# HC32M413 register map
File version: 1.0
CPU: CM4 r0p1, little endian, MPU, FPU, 4 interrupt priority bits
Registers are 32-bit, read-write, reset 0x0 unless marked. A register's access mark holds for its fields unless they carry their own. Offsets are from the block's base; [hi:lo] are bit positions; {n}, {i} and the like mark numbered series.

## CMP_COMMON
Base 0x4004A000; alternate view of CMP1
0x0C DADR 16-bit
  [11:0] DADR
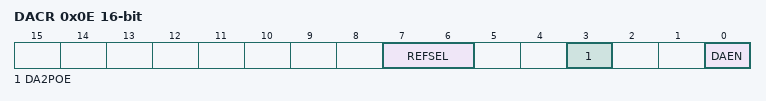
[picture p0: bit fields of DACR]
0x0E DACR 16-bit
  [7:6] REFSEL, [3] DA2POE, [0] DAEN

## CMU
Base 0x40054400
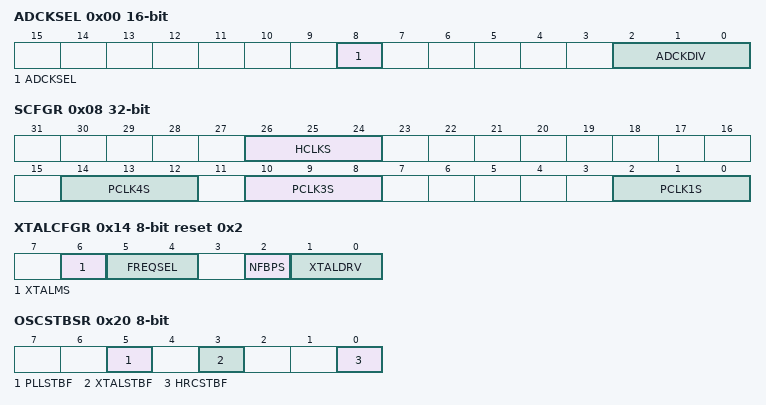
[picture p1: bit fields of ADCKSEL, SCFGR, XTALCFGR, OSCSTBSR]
0x00 ADCKSEL 16-bit
  [8] ADCKSEL, [2:0] ADCKDIV
0x04 XTALSTDSR 8-bit
  [0] XTALSTDF
0x08 SCFGR
  [26:24] HCLKS, [14:12] PCLK4S, [10:8] PCLK3S, [2:0] PCLK1S
0x0C CKSWR 8-bit reset 0x1
  [2:0] CKSW
0x10 XTALCR 8-bit reset 0x1
  [0] XTALSTP
0x14 XTALCFGR 8-bit reset 0x2
  [6] XTALMS, [5:4] FREQSEL, [2] NFBPS, [1:0] XTALDRV
0x15 XTALSTBCR 8-bit
  [2:0] XTALSTB
0x18 HRCCR 8-bit
  [0] HRCSTP
0x20 OSCSTBSR 8-bit ro
  [5] PLLSTBF, [3] XTALSTBF, [0] HRCSTBF
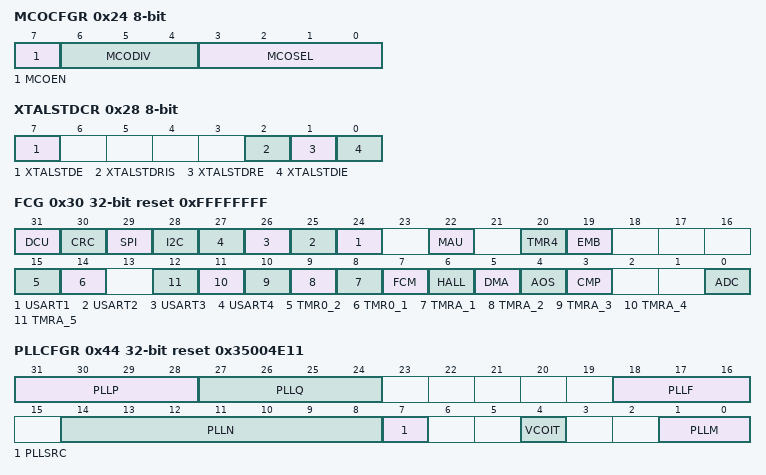
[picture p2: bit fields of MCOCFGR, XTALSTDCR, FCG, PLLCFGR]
0x24 MCOCFGR 8-bit
  [7] MCOEN, [6:4] MCODIV, [3:0] MCOSEL
0x28 XTALSTDCR 8-bit
  [7] XTALSTDE, [2] XTALSTDRIS, [1] XTALSTDRE, [0] XTALSTDIE
0x30 FCG reset 0xFFFFFFFF
  [31] DCU, [30] CRC, [29] SPI, [28] I2C, [n+23] USART{n} (n=1..4), [22] MAU, [20] TMR4, [19] EMB, [15] TMR0_2, [14] TMR0_1, [n+7] TMRA_{n} (n=1..5), [7] FCM, [6] HALL, [5] DMA, [4] AOS, [3] CMP, [0] ADC
0x3C LRCCR 8-bit
  [0] LRCSTP
0x40 MRCCR 8-bit
  [0] MRCSTP
0x44 PLLCFGR reset 0x35004E11
  [31:28] PLLP, [27:24] PLLQ, [18:16] PLLF, [14:8] PLLN, [7] PLLSRC, [4] VCOIT, [1:0] PLLM
0x48 PLLCR 8-bit reset 0x1
  [0] PLLOFF

## CRC
Base 0x40050400
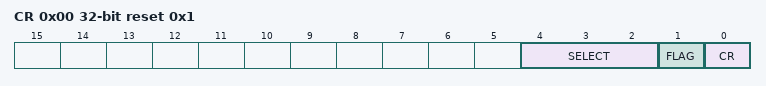
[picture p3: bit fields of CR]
0x00 CR reset 0x1
  [4:2] SELECT, [1] FLAG ro, [0] CR
0x04 RESLT1
0x08 RESLT2
{0x80+4i} DAT{i} wo (i=0..31)

## DBGC
Base 0xE0042000
0x0C CHIPID ro reset 0x58480413
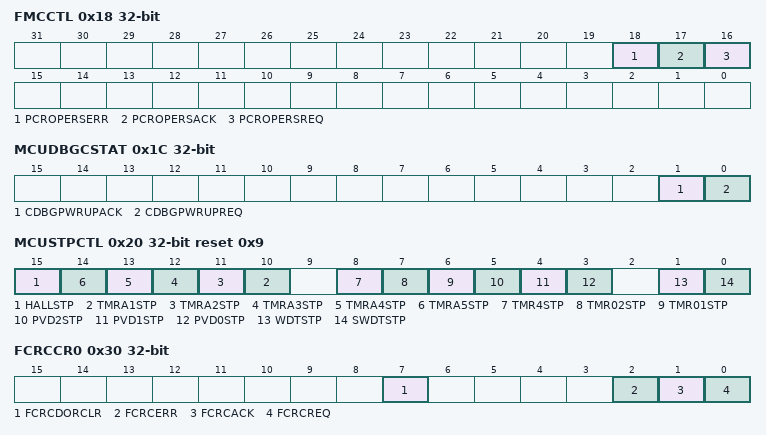
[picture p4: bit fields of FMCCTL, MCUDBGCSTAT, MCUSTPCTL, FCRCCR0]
0x18 FMCCTL
  [18] PCROPERSERR, [17] PCROPERSACK, [16] PCROPERSREQ
0x1C MCUDBGCSTAT
  [1] CDBGPWRUPACK, [0] CDBGPWRUPREQ
0x20 MCUSTPCTL reset 0x9
  [15] HALLSTP, [n+9] TMRA{n}STP (n=1..5), [8] TMR4STP, [7] TMR02STP, [6] TMR01STP, [5] PVD2STP, [4] PVD1STP, [3] PVD0STP, [1] WDTSTP, [0] SWDTSTP
0x30 FCRCCR0
  [7] FCRCDORCLR, [2] FCRCERR, [1] FCRCACK, [0] FCRCREQ
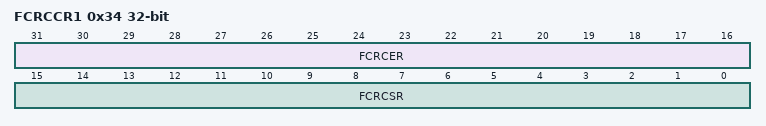
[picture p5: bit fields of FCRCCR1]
0x34 FCRCCR1
  [31:16] FCRCER, [15:0] FCRCSR
0x38 FCRCDOR ro
0x3C FCRCREF ro

## DCU
Base 0x40052000
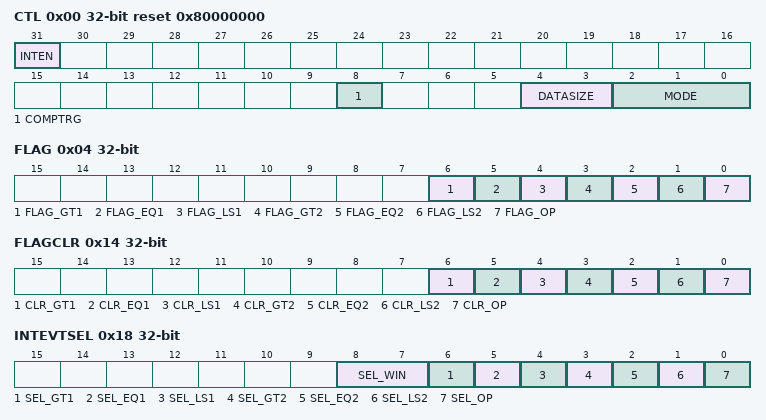
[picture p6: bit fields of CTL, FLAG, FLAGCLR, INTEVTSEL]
0x00 CTL reset 0x80000000
  [31] INTEN, [8] COMPTRG, [4:3] DATASIZE, [2:0] MODE
0x04 FLAG ro
  [6] FLAG_GT1, [5] FLAG_EQ1, [4] FLAG_LS1, [3] FLAG_GT2, [2] FLAG_EQ2, [1] FLAG_LS2, [0] FLAG_OP
{0x8+4i} DATA{i} (i=0..2)
0x14 FLAGCLR wo
  [6] CLR_GT1, [5] CLR_EQ1, [4] CLR_LS1, [3] CLR_GT2, [2] CLR_EQ2, [1] CLR_LS2, [0] CLR_OP
0x18 INTEVTSEL
  [8:7] SEL_WIN, [6] SEL_GT1, [5] SEL_EQ1, [4] SEL_LS1, [3] SEL_GT2, [2] SEL_EQ2, [1] SEL_LS2, [0] SEL_OP

## DMA
Base 0x40053000
0x00 EN
  [0] EN
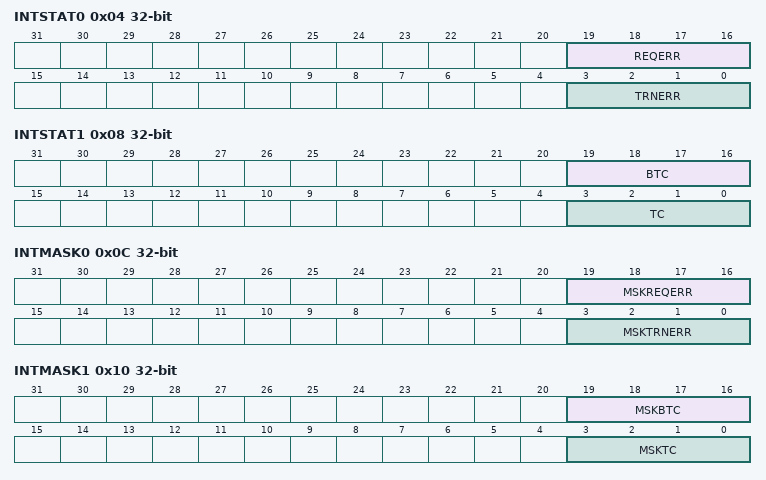
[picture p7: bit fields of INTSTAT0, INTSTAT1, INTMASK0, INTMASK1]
0x04 INTSTAT0 ro
  [19:16] REQERR, [3:0] TRNERR
0x08 INTSTAT1 ro
  [19:16] BTC, [3:0] TC
0x0C INTMASK0
  [19:16] MSKREQERR, [3:0] MSKTRNERR
0x10 INTMASK1
  [19:16] MSKBTC, [3:0] MSKTC
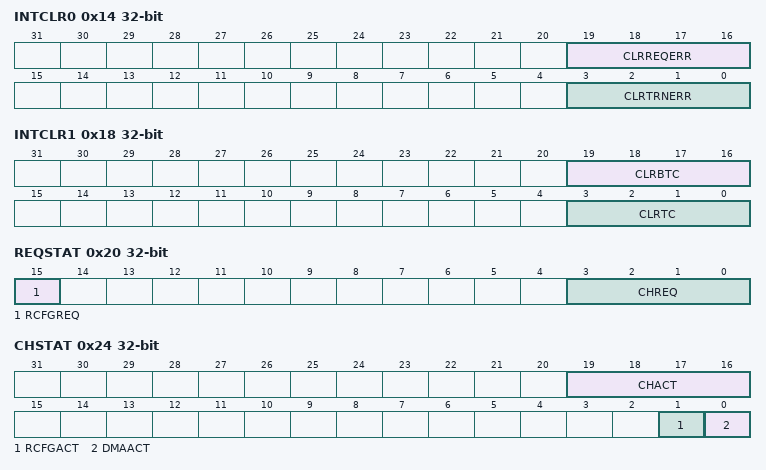
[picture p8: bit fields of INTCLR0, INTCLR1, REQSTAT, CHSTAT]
0x14 INTCLR0
  [19:16] CLRREQERR, [3:0] CLRTRNERR
0x18 INTCLR1
  [19:16] CLRBTC, [3:0] CLRTC
0x1C CHEN
  [3:0] CHEN
0x20 REQSTAT ro
  [15] RCFGREQ, [3:0] CHREQ
0x24 CHSTAT ro
  [19:16] CHACT, [1] RCFGACT, [0] DMAACT
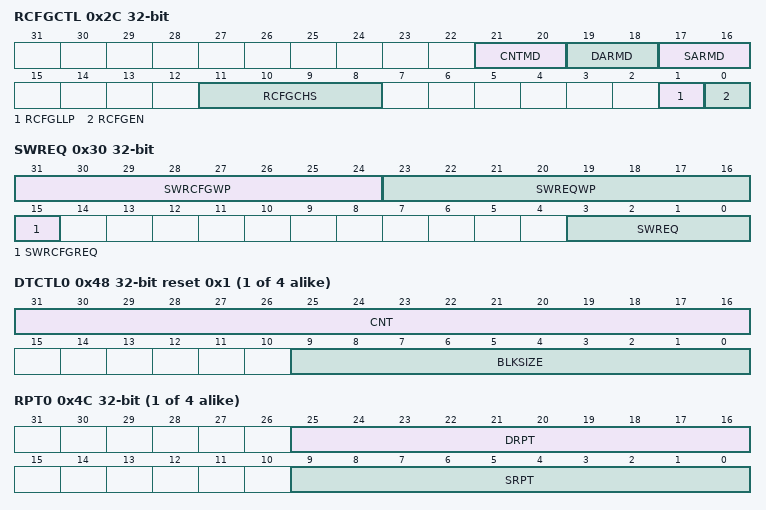
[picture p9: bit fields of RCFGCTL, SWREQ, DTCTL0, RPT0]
0x2C RCFGCTL
  [21:20] CNTMD, [19:18] DARMD, [17:16] SARMD, [11:8] RCFGCHS, [1] RCFGLLP, [0] RCFGEN
0x30 SWREQ wo
  [31:24] SWRCFGWP, [23:16] SWREQWP, [15] SWRCFGREQ, [3:0] SWREQ
0x34 CHENCLR wo
  [3:0] CHENCLR
{0x40+0x40*i} SAR{i} (i=0..3)
{0x44+0x40*i} DAR{i} (i=0..3)
{0x48+0x40*i} DTCTL{i} reset 0x1 (i=0..3)
  [31:16] CNT, [9:0] BLKSIZE
{0x4C+0x40*i} RPT{i} (i=0..3)
  [25:16] DRPT, [9:0] SRPT
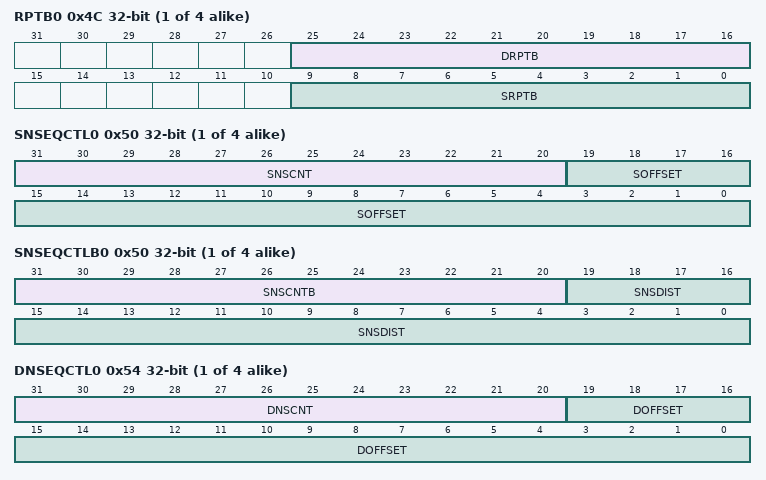
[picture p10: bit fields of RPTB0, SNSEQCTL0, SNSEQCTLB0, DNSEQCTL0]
{0x4C+0x40*i} RPTB{i} (alternate view of RPT{i}) (i=0..3)
  [25:16] DRPTB, [9:0] SRPTB
{0x50+0x40*i} SNSEQCTL{i} (i=0..3)
  [31:20] SNSCNT, [19:0] SOFFSET
{0x50+0x40*i} SNSEQCTLB{i} (alternate view of SNSEQCTL{i}) (i=0..3)
  [31:20] SNSCNTB, [19:0] SNSDIST
{0x54+0x40*i} DNSEQCTL{i} (i=0..3)
  [31:20] DNSCNT, [19:0] DOFFSET
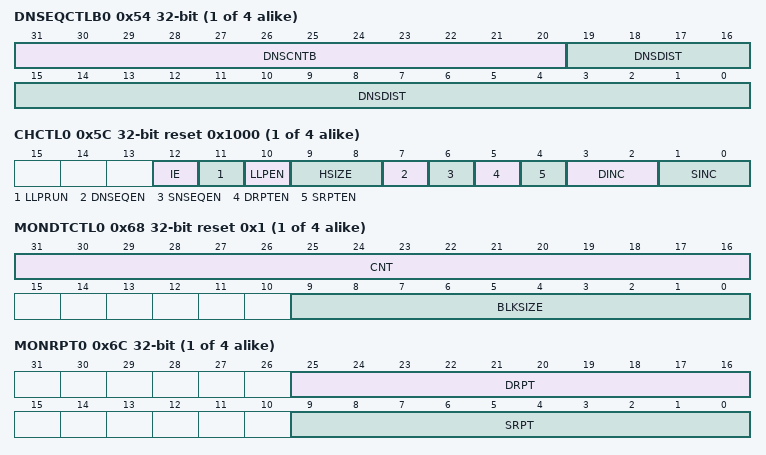
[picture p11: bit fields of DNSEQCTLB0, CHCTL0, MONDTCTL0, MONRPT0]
{0x54+0x40*i} DNSEQCTLB{i} (alternate view of DNSEQCTL{i}) (i=0..3)
  [31:20] DNSCNTB, [19:0] DNSDIST
{0x58+0x40*i} LLP{i} (i=0..3)
  [31:2] LLP
{0x5C+0x40*i} CHCTL{i} reset 0x1000 (i=0..3)
  [12] IE, [11] LLPRUN, [10] LLPEN, [9:8] HSIZE, [7] DNSEQEN, [6] SNSEQEN, [5] DRPTEN, [4] SRPTEN, [3:2] DINC, [1:0] SINC
{0x60+0x40*i} MONSAR{i} ro (i=0..3)
{0x64+0x40*i} MONDAR{i} ro (i=0..3)
{0x68+0x40*i} MONDTCTL{i} ro reset 0x1 (i=0..3)
  [31:16] CNT, [9:0] BLKSIZE
{0x6C+0x40*i} MONRPT{i} ro (i=0..3)
  [25:16] DRPT, [9:0] SRPT
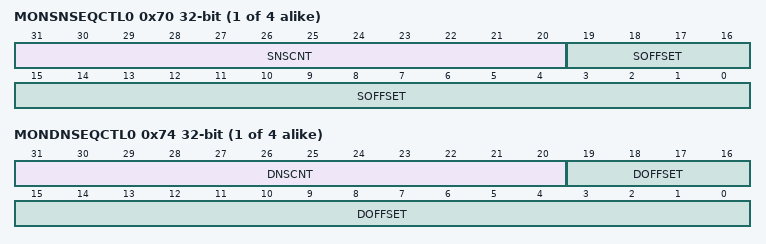
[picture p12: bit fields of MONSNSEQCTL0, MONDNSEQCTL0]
{0x70+0x40*i} MONSNSEQCTL{i} ro (i=0..3)
  [31:20] SNSCNT, [19:0] SOFFSET
{0x74+0x40*i} MONDNSEQCTL{i} ro (i=0..3)
  [31:20] DNSCNT, [19:0] DOFFSET
